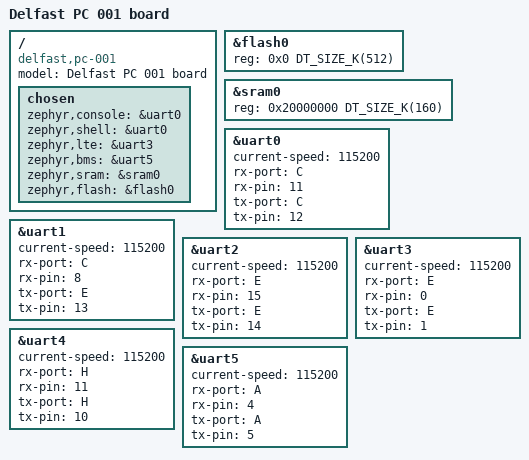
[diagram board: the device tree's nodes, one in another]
/*
 * Copyright (c) 2021 BaDen
 *
 * SPDX-License-Identifier: Apache-2.0
 */

/dts-v1/;
#include <nuvoton/delfast-m48x.dtsi>

/ {
	model = "Delfast PC 001 board";
	compatible = "delfast,pc-001", "nuvoton,m487";

	// aliases {
	// 	led0 = &red_led_1;
	// };

	chosen {
		zephyr,console = &uart0;
		zephyr,shell = &uart0;
        zephyr,lte = &uart3;
        zephyr,bms = &uart5;
		zephyr,sram = &sram0;
		zephyr,flash = &flash0;
	};

	// examplesensor0: examplesensor_0 {
	// 	compatible = "zephyr,examplesensor";
	// 	label = "EXAMPLESENSOR_0";
	// 	input-gpios = <1 2 3>;
	// 	// input-gpios = <&gpio0 11 (GPIO_PULL_UP | GPIO_ACTIVE_LOW)>;
	// };

	// leds {
	// 	compatible = "gpio-leds";
	// 	red_led_1: led_1 {
	// 		gpios = <&gpioh 0 GPIO_ACTIVE_HIGH>;
	// 		label = "LED1";
	// 	};
	// };

	// soc {
	// 	pinctrl: pin-controller@0 {
	// 		compatible = "nuvoton,npcx-pinctrl-def";
	// 	}
	// }

};

// soc {
// 	m48x_gpio: gpio {
// 		compatible = "delfast,gpio";
// 		gpio-controller;
// 		label = "DELFAST_GPIO";
// 		ngpios = <7>;
// 		#gpio-cells = <2>;
// 	};
// };


&flash0 {
	reg = <0x0 DT_SIZE_K(512)>;
};

&sram0 {
	reg = <0x20000000 DT_SIZE_K(160)>;
};

&uart0 {
	current-speed = <115200>;
	status = "okay";
    rx-port = "C";
    rx-pin = "11";
    tx-port = "C";
    tx-pin = "12";
    /*rx-gpios = <&porta 0>;*/
};

/*rx-gpios = <&pinmux_a 0>;
tx-gpios = <&pinmux_a 1>;*/

&uart1 {
	current-speed = <115200>;
	status = "okay";
    rx-port = "C";
    rx-pin = "8";
    tx-port = "E";
    tx-pin = "13";
};

&uart2 {
	current-speed = <115200>;
	status = "okay";
    rx-port = "E";
    rx-pin = "15";
    tx-port = "E";
    tx-pin = "14";
};

&uart3 {
	current-speed = <115200>;
	status = "okay";
    rx-port = "E";
    rx-pin = "0";
    tx-port = "E";
    tx-pin = "1";
};

&uart4 {
	current-speed = <115200>;
	status = "okay";
    rx-port = "H";
    rx-pin = "11";
    tx-port = "H";
    tx-pin = "10";
};

&uart5 {
	current-speed = <115200>;
	status = "okay";
    rx-port = "A";
    rx-pin = "4";
    tx-port = "A";
    tx-pin = "5";
};
